# MIMXRT1052 register map
Vendor: nxp.com; File version: 1.0
CPU: CM7 r0p1, little endian, MPU, FPU, VTOR, 4 interrupt priority bits
Registers are 32-bit, read-write, reset 0x0 unless marked. A register's access mark holds for its fields unless they carry their own. Offsets are from the block's base; [hi:lo] are bit positions.

## DCDC
Base 0x40080000
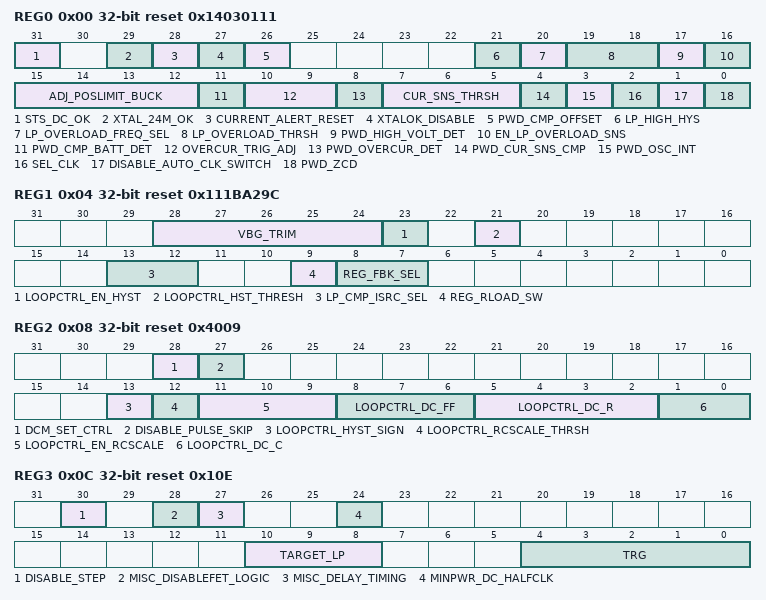
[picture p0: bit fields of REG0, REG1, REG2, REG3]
0x00 REG0 reset 0x14030111 — DCDC Register 0
  [31] STS_DC_OK ro — Status register to indicate DCDC status. 1'b1: DCDC already settled 1'b0: DCDC is settling
  [29] XTAL_24M_OK — set to 1 to switch internal ring osc to xtal 24M
  [28] CURRENT_ALERT_RESET — reset current alert signal
  [27] XTALOK_DISABLE — 1'b1: Disable xtalok detection circuit 1'b0: Enable xtalok detection circuit
  [26] PWD_CMP_OFFSET — power down output range comparator
  [21] LP_HIGH_HYS — Adjust hysteretic value in low power from 12.5mV to 25mV
  [20] LP_OVERLOAD_FREQ_SEL — the period of counting the charging times in power save mode 0: eight 32k cycle 1: sixteen 32k cycle
  [19:18] LP_OVERLOAD_THRSH — the threshold of the counting number of charging times during the period that lp_overload_freq_sel sets in power save mode
  [17] PWD_HIGH_VOLT_DET — power down overvoltage detection comparator
  [16] EN_LP_OVERLOAD_SNS — enable the overload detection in power save mode, if current is larger than the overloading threshold (typical value is 50 mA), DCDC will switch to the run mode automatically
  [15:12] ADJ_POSLIMIT_BUCK — adjust value to poslimit_buck register
  [11] PWD_CMP_BATT_DET — set to "1" to power down the low voltage detection comparator
  [10:9] OVERCUR_TRIG_ADJ — The threshold of over current detection in run mode and power save mode: run mode power save mode 0x0 1 A 0
  [8] PWD_OVERCUR_DET — power down overcurrent detection comparator
  [7:5] CUR_SNS_THRSH — Set the threshold of current detector, if the peak current of the inductor exceeds the threshold, the current detector will assert
  [4] PWD_CUR_SNS_CMP — The power down signal of the current detector.
  [3] PWD_OSC_INT — Power down internal osc. Only set this bit, when 24 MHz crystal osc is available
  [2] SEL_CLK — select 24 MHz Crystal clock for DCDC, when dcdc_disable_auto_clk_switch is set.
  [1] DISABLE_AUTO_CLK_SWITCH — Disable automatic clock switch from internal osc to xtal clock.
  [0] PWD_ZCD — power down the zero cross detection function for discontinuous conductor mode
0x04 REG1 reset 0x111BA29C — DCDC Register 1
  [28:24] VBG_TRIM — trim bandgap voltage
  [23] LOOPCTRL_EN_HYST — Enable hysteresis in switching converter common mode analog comparators
  [21] LOOPCTRL_HST_THRESH — increase the threshold detection for common mode analog comparator
  [13:12] LP_CMP_ISRC_SEL — set the current bias of low power comparator 0x0: 50 nA 0x1: 100 nA 0x2: 200 nA 0x3: 400 nA
  [9] REG_RLOAD_SW — control the load resistor of the internal regulator of DCDC, the load resistor is connected as default "1", and need set to "0" to disconnect the load resistor
  [8:7] REG_FBK_SEL — select the feedback point of the internal regulator
0x08 REG2 reset 0x4009 — DCDC Register 2
  [28] DCM_SET_CTRL — Set high to improve the transition from heavy load to light load
  [27] DISABLE_PULSE_SKIP — Set to "0" : stop charging if the duty cycle is lower than what set by dcdc_neglimit_in
  [13] LOOPCTRL_HYST_SIGN — Invert the sign of the hysteresis in DC-DC analog comparators.
  [12] LOOPCTRL_RCSCALE_THRSH — Increase the threshold detection for RC scale circuit.
  [11:9] LOOPCTRL_EN_RCSCALE — Enable analog circuit of DC-DC converter to respond faster under transient load conditions.
  [8:6] LOOPCTRL_DC_FF — Two's complement feed forward step in duty cycle in the switching DC-DC converter
  [5:2] LOOPCTRL_DC_R — Magnitude of proportional control parameter in the switching DC-DC converter control loop.
  [1:0] LOOPCTRL_DC_C — Ratio of integral control parameter to proportional control parameter in the switching DC-DC converter, and can be used to optimize efficiency and loop response
0x0C REG3 reset 0x10E — DCDC Register 3
  [30] DISABLE_STEP — Disable stepping for the output VDD_SOC of DCDC
  [28] MISC_DISABLEFET_LOGIC — Reserved
  [27] MISC_DELAY_TIMING — Ajust delay to reduce ground noise
  [24] MINPWR_DC_HALFCLK — Set DCDC clock to half freqeuncy for continuous mode
  [10:8] TARGET_LP — Target value of standby (low power) mode 0x0: 0
  [4:0] TRG — Target value of VDD_SOC, 25 mV each step 0x0: 0.8V 0xE: 1.15V 0x1F:1.575V

## Notices in the file
Copyright 2016-2019 NXP
All rights reserved.
SPDX-License-Identifier: BSD-3-Clause
